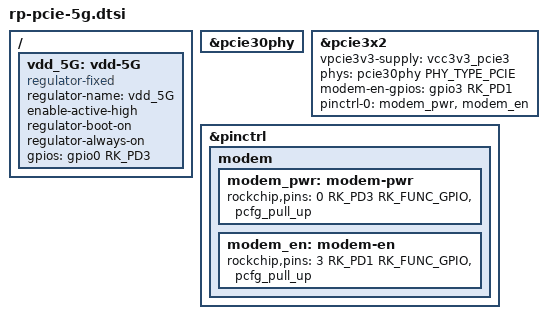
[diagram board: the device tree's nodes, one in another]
/{
        vdd_5G: vdd-5G{
                compatible = "regulator-fixed";
                regulator-name = "vdd_5G";
                enable-active-high;
                regulator-boot-on;
                regulator-always-on;
                gpios = <&gpio0 RK_PD3 GPIO_ACTIVE_HIGH>;
        };
};

&pcie30phy { 
        status = "okay"; 
};

&pcie3x2 { 
        status = "okay";
        vpcie3v3-supply = <&vcc3v3_pcie3>;
        phys = <&pcie30phy PHY_TYPE_PCIE>; 
       // reset-gpios = <&gpio2 RK_PC5 GPIO_ACTIVE_HIGH>;
       //modem-pwr-gpios = <&gpio0 RK_PD3 GPIO_ACTIVE_HIGH>;
        modem-en-gpios = <&gpio3 RK_PD1 GPIO_ACTIVE_HIGH>;
       // pcie-waken-gpios = <&gpio3 RK_PC5 GPIO_ACTIVE_HIGH>;
        
        pinctrl-names = "default";
        pinctrl-0 = <&modem_pwr>,<&modem_en>;
};


&pinctrl {
    modem {
        modem_pwr: modem-pwr {
            rockchip,pins = <0 RK_PD3 RK_FUNC_GPIO &pcfg_pull_up>;
        };
        modem_en: modem-en {
            rockchip,pins = <3 RK_PD1 RK_FUNC_GPIO &pcfg_pull_up>;
        };
//        modem_rst: modem-rst {
//            rockchip,pins = <2 RK_PC5 RK_FUNC_GPIO &pcfg_pull_up>;
//        };
//        modem_wakup: modem-wakup {
//            rockchip,pins = <3 RK_PC5 RK_FUNC_GPIO &pcfg_pull_up>;
//        };
    };
};

